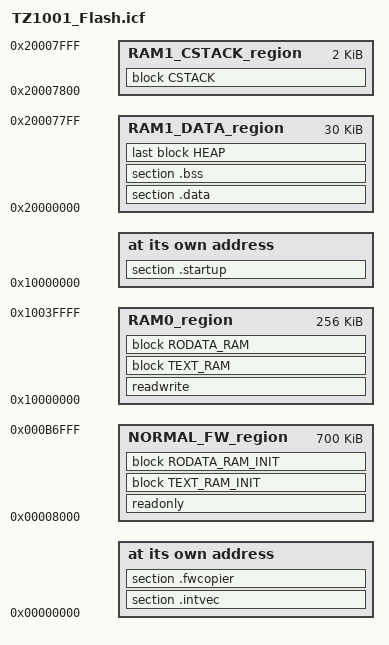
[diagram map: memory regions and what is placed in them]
/*###ICF### Section handled by ICF editor, don't touch! ****/
/*-Editor annotation file-*/
/* IcfEditorFile="$TOOLKIT_DIR$\config\ide\IcfEditor\cortex_v1_0.xml" */
/*-Specials-*/
define symbol __ICFEDIT_intvec_start__ = 0x00000000;
define symbol RAM_intvec_start = 0x10000000;

/*-Memory Regions-*/

define symbol __ICFEDIT_normal_fw_start__   = 0x00008000;
define symbol __ICFEDIT_normal_fw_end__     = 0x000b6fff;
define symbol __ICFEDIT_region_RAM0_start__ = 0x10000000;
define symbol __ICFEDIT_region_RAM0_end__   = 0x1003FFFF;
define symbol __ICFEDIT_region_RAM1_start__ = 0x20000000;
define symbol __ICFEDIT_region_RAM1_end__   = 0x20007FFF;

/* Stack 1/8 and Heap 1/4 of RAM */
define symbol __ICFEDIT_size_cstack__ = 0x0800;
define symbol __ICFEDIT_size_heap__   = 0x1C00;
/**** End of ICF editor section. ###ICF###*/

define memory mem with size = 4G;
define region NORMAL_FW_region      = mem:[from __ICFEDIT_normal_fw_start__ to __ICFEDIT_normal_fw_end__];
define region RAM0_region           = mem:[from __ICFEDIT_region_RAM0_start__ to __ICFEDIT_region_RAM0_end__];
define region RAM1_DATA_region      = mem:[from __ICFEDIT_region_RAM1_start__ to __ICFEDIT_region_RAM1_end__ - __ICFEDIT_size_cstack__];
define region RAM1_CSTACK_region    = mem:[from __ICFEDIT_region_RAM1_end__ - __ICFEDIT_size_cstack__ + 1 to __ICFEDIT_region_RAM1_end__];

define block CSTACK             with alignment = 8, size = __ICFEDIT_size_cstack__   { };
define block HEAP               with alignment = 8, size = __ICFEDIT_size_heap__     { };
define block RODATA_RAM_INIT    with alignment = 4 { section .rodata_init };
define block RODATA_RAM         with alignment = 4 { section .rodata };
define block TEXT_RAM_INIT      with alignment = 4 { readonly section .text_init };
define block TEXT_RAM           with alignment = 4 { readwrite section .text };

initialize manually { section .startup, section .rodata, section .text };
initialize by copy with packing = none { readwrite };
do not initialize   { section .noinit };

place at address mem:__ICFEDIT_intvec_start__ { section .intvec, section .fwcopier};
place at address mem:RAM_intvec_start         { section .startup };

place in NORMAL_FW_region   { readonly, block TEXT_RAM_INIT, block RODATA_RAM_INIT};
place in RAM0_region  { readwrite, block TEXT_RAM, block RODATA_RAM};
place in RAM1_DATA_region { section .data, section .bss };
place in RAM1_DATA_region { last block HEAP };
place in RAM1_CSTACK_region { block CSTACK };

/* 2015/02/18 *//* F0.2 */
